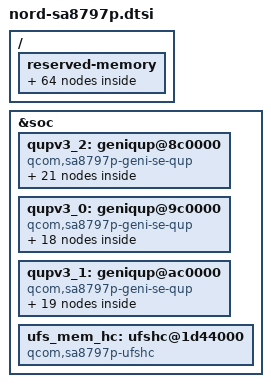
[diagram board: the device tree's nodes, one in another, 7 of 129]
// SPDX-License-Identifier: BSD-3-Clause
/*
 * Copyright (c) Qualcomm Technologies, Inc. and/or its subsidiaries.
 */

#include "nord.dtsi"
#include "scmi-common.dtsi"

/ {
	reserved-memory {
		shmem0: scmi-shmem@d7600000 {
			compatible = "arm,scmi-shmem";
			reg = <0x0 0xd7600000 0x0 0x1000>;
			no-map;
		};

		shmem1: scmi-shmem@d7601000 {
			compatible = "arm,scmi-shmem";
			reg = <0x0 0xd7601000 0x0 0x1000>;
			no-map;
		};

		shmem2: scmi-shmem@d7602000 {
			compatible = "arm,scmi-shmem";
			reg = <0x0 0xd7602000 0x0 0x1000>;
			no-map;
		};

		shmem3: scmi-shmem@d7603000 {
			compatible = "arm,scmi-shmem";
			reg = <0x0 0xd7603000 0x0 0x1000>;
			no-map;
		};

		shmem4: scmi-shmem@d7604000 {
			compatible = "arm,scmi-shmem";
			reg = <0x0 0xd7604000 0x0 0x1000>;
			no-map;
		};

		shmem5: scmi-shmem@d7605000 {
			compatible = "arm,scmi-shmem";
			reg = <0x0 0xd7605000 0x0 0x1000>;
			no-map;
		};

		shmem6: scmi-shmem@d7606000 {
			compatible = "arm,scmi-shmem";
			reg = <0x0 0xd7606000 0x0 0x1000>;
			no-map;
		};

		shmem7: scmi-shmem@d7607000 {
			compatible = "arm,scmi-shmem";
			reg = <0x0 0xd7607000 0x0 0x1000>;
			no-map;
		};

		shmem8: scmi-shmem@d7608000 {
			compatible = "arm,scmi-shmem";
			reg = <0x0 0xd7608000 0x0 0x1000>;
			no-map;
		};

		shmem9: scmi-shmem@d7609000 {
			compatible = "arm,scmi-shmem";
			reg = <0x0 0xd7609000 0x0 0x1000>;
			no-map;
		};

		shmem10: scmi-shmem@d760a000 {
			compatible = "arm,scmi-shmem";
			reg = <0x0 0xd760a000 0x0 0x1000>;
			no-map;
		};

		shmem11: scmi-shmem@d760b000 {
			compatible = "arm,scmi-shmem";
			reg = <0x0 0xd760b000 0x0 0x1000>;
			no-map;
		};

		shmem12: scmi-shmem@d760c000 {
			compatible = "arm,scmi-shmem";
			reg = <0x0 0xd760c000 0x0 0x1000>;
			no-map;
		};

		shmem13: scmi-shmem@d760d000 {
			compatible = "arm,scmi-shmem";
			reg = <0x0 0xd760d000 0x0 0x1000>;
			no-map;
		};

		shmem14: scmi-shmem@d760e000 {
			compatible = "arm,scmi-shmem";
			reg = <0x0 0xd760e000 0x0 0x1000>;
			no-map;
		};

		shmem15: scmi-shmem@d760f000 {
			compatible = "arm,scmi-shmem";
			reg = <0x0 0xd760f000 0x0 0x1000>;
			no-map;
		};

		shmem16: scmi-shmem@d7610000 {
			compatible = "arm,scmi-shmem";
			reg = <0x0 0xd7610000 0x0 0x1000>;
			no-map;
		};

		shmem17: scmi-shmem@d7611000 {
			compatible = "arm,scmi-shmem";
			reg = <0x0 0xd7611000 0x0 0x1000>;
			no-map;
		};

		shmem18: scmi-shmem@d7612000 {
			compatible = "arm,scmi-shmem";
			reg = <0x0 0xd7612000 0x0 0x1000>;
			no-map;
		};

		shmem19: scmi-shmem@d7613000 {
			compatible = "arm,scmi-shmem";
			reg = <0x0 0xd7613000 0x0 0x1000>;
			no-map;
		};

		shmem20: scmi-shmem@d7614000 {
			compatible = "arm,scmi-shmem";
			reg = <0x0 0xd7614000 0x0 0x1000>;
			no-map;
		};

		shmem21: scmi-shmem@d7615000 {
			compatible = "arm,scmi-shmem";
			reg = <0x0 0xd7615000 0x0 0x1000>;
			no-map;
		};

		shmem22: scmi-shmem@d7616000 {
			compatible = "arm,scmi-shmem";
			reg = <0x0 0xd7616000 0x0 0x1000>;
			no-map;
		};

		shmem23: scmi-shmem@d7617000 {
			compatible = "arm,scmi-shmem";
			reg = <0x0 0xd7617000 0x0 0x1000>;
			no-map;
		};

		shmem24: scmi-shmem@d7618000 {
			compatible = "arm,scmi-shmem";
			reg = <0x0 0xd7618000 0x0 0x1000>;
			no-map;
		};

		shmem25: scmi-shmem@d7619000 {
			compatible = "arm,scmi-shmem";
			reg = <0x0 0xd7619000 0x0 0x1000>;
			no-map;
		};

		shmem26: scmi-shmem@d761a000 {
			compatible = "arm,scmi-shmem";
			reg = <0x0 0xd761a000 0x0 0x1000>;
			no-map;
		};

		shmem27: scmi-shmem@d761b000 {
			compatible = "arm,scmi-shmem";
			reg = <0x0 0xd761b000 0x0 0x1000>;
			no-map;
		};

		shmem28: scmi-shmem@d761c000 {
			compatible = "arm,scmi-shmem";
			reg = <0x0 0xd761c000 0x0 0x1000>;
			no-map;
		};

		shmem29: scmi-shmem@d761d000 {
			compatible = "arm,scmi-shmem";
			reg = <0x0 0xd761d000 0x0 0x1000>;
			no-map;
		};

		shmem30: scmi-shmem@d761e000 {
			compatible = "arm,scmi-shmem";
			reg = <0x0 0xd761e000 0x0 0x1000>;
			no-map;
		};

		shmem31: scmi-shmem@d761f000 {
			compatible = "arm,scmi-shmem";
			reg = <0x0 0xd761f000 0x0 0x1000>;
			no-map;
		};

		shmem32: scmi-shmem@d7620000 {
			compatible = "arm,scmi-shmem";
			reg = <0x0 0xd7620000 0x0 0x1000>;
			no-map;
		};

		shmem33: scmi-shmem@d7621000 {
			compatible = "arm,scmi-shmem";
			reg = <0x0 0xd7621000 0x0 0x1000>;
			no-map;
		};

		shmem34: scmi-shmem@d7622000 {
			compatible = "arm,scmi-shmem";
			reg = <0x0 0xd7622000 0x0 0x1000>;
			no-map;
		};

		shmem35: scmi-shmem@d7623000 {
			compatible = "arm,scmi-shmem";
			reg = <0x0 0xd7623000 0x0 0x1000>;
			no-map;
		};

		shmem36: scmi-shmem@d7624000 {
			compatible = "arm,scmi-shmem";
			reg = <0x0 0xd7624000 0x0 0x1000>;
			no-map;
		};

		shmem37: scmi-shmem@d7625000 {
			compatible = "arm,scmi-shmem";
			reg = <0x0 0xd7625000 0x0 0x1000>;
			no-map;
		};

		shmem38: scmi-shmem@d7626000 {
			compatible = "arm,scmi-shmem";
			reg = <0x0 0xd7626000 0x0 0x1000>;
			no-map;
		};

		shmem39: scmi-shmem@d7627000 {
			compatible = "arm,scmi-shmem";
			reg = <0x0 0xd7627000 0x0 0x1000>;
			no-map;
		};

		shmem40: scmi-shmem@d7628000 {
			compatible = "arm,scmi-shmem";
			reg = <0x0 0xd7628000 0x0 0x1000>;
			no-map;
		};

		shmem41: scmi-shmem@d7629000 {
			compatible = "arm,scmi-shmem";
			reg = <0x0 0xd7629000 0x0 0x1000>;
			no-map;
		};

		shmem42: scmi-shmem@d762a000 {
			compatible = "arm,scmi-shmem";
			reg = <0x0 0xd762a000 0x0 0x1000>;
			no-map;
		};

		shmem43: scmi-shmem@d762b000 {
			compatible = "arm,scmi-shmem";
			reg = <0x0 0xd762b000 0x0 0x1000>;
			no-map;
		};

		shmem44: scmi-shmem@d762c000 {
			compatible = "arm,scmi-shmem";
			reg = <0x0 0xd762c000 0x0 0x1000>;
			no-map;
		};

		shmem45: scmi-shmem@d762d000 {
			compatible = "arm,scmi-shmem";
			reg = <0x0 0xd762d000 0x0 0x1000>;
			no-map;
		};

		shmem46: scmi-shmem@d762e000 {
			compatible = "arm,scmi-shmem";
			reg = <0x0 0xd762e000 0x0 0x1000>;
			no-map;
		};

		shmem47: scmi-shmem@d762f000 {
			compatible = "arm,scmi-shmem";
			reg = <0x0 0xd762f000 0x0 0x1000>;
			no-map;
		};

		shmem48: scmi-shmem@d7630000 {
			compatible = "arm,scmi-shmem";
			reg = <0x0 0xd7630000 0x0 0x1000>;
			no-map;
		};

		shmem49: scmi-shmem@d7631000 {
			compatible = "arm,scmi-shmem";
			reg = <0x0 0xd7631000 0x0 0x1000>;
			no-map;
		};

		shmem50: scmi-shmem@d7632000 {
			compatible = "arm,scmi-shmem";
			reg = <0x0 0xd7632000 0x0 0x1000>;
			no-map;
		};

		shmem51: scmi-shmem@d7633000 {
			compatible = "arm,scmi-shmem";
			reg = <0x0 0xd7633000 0x0 0x1000>;
			no-map;
		};

		shmem52: scmi-shmem@d7634000 {
			compatible = "arm,scmi-shmem";
			reg = <0x0 0xd7634000 0x0 0x1000>;
			no-map;
		};

		shmem53: scmi-shmem@d7635000 {
			compatible = "arm,scmi-shmem";
			reg = <0x0 0xd7635000 0x0 0x1000>;
			no-map;
		};

		shmem54: scmi-shmem@d7636000 {
			compatible = "arm,scmi-shmem";
			reg = <0x0 0xd7636000 0x0 0x1000>;
			no-map;
		};

		shmem55: scmi-shmem@d7637000 {
			compatible = "arm,scmi-shmem";
			reg = <0x0 0xd7637000 0x0 0x1000>;
			no-map;
		};

		shmem56: scmi-shmem@d7638000 {
			compatible = "arm,scmi-shmem";
			reg = <0x0 0xd7638000 0x0 0x1000>;
			no-map;
		};

		shmem57: scmi-shmem@d7639000 {
			compatible = "arm,scmi-shmem";
			reg = <0x0 0xd7639000 0x0 0x1000>;
			no-map;
		};

		shmem58: scmi-shmem@d763a000 {
			compatible = "arm,scmi-shmem";
			reg = <0x0 0xd763a000 0x0 0x1000>;
			no-map;
		};

		shmem59: scmi-shmem@d763b000 {
			compatible = "arm,scmi-shmem";
			reg = <0x0 0xd763b000 0x0 0x1000>;
			no-map;
		};

		shmem60: scmi-shmem@d763c000 {
			compatible = "arm,scmi-shmem";
			reg = <0x0 0xd763c000 0x0 0x1000>;
			no-map;
		};

		shmem61: scmi-shmem@d763d000 {
			compatible = "arm,scmi-shmem";
			reg = <0x0 0xd763d000 0x0 0x1000>;
			no-map;
		};

		shmem62: scmi-shmem@d763e000 {
			compatible = "arm,scmi-shmem";
			reg = <0x0 0xd763e000 0x0 0x1000>;
			no-map;
		};

		shmem63: scmi-shmem@d763f000 {
			compatible = "arm,scmi-shmem";
			reg = <0x0 0xd763f000 0x0 0x1000>;
			no-map;
		};
	};
};

&soc {
	qupv3_2: geniqup@8c0000 {
		compatible = "qcom,sa8797p-geni-se-qup",
			     "qcom,sa8255p-geni-se-qup";

		i2c14: i2c@880000 {
			compatible = "qcom,sa8797p-geni-i2c",
				     "qcom,sa8255p-geni-i2c";
			power-domains = <&scmi11_pd 14>,
					<&scmi11_dvfs 14>;
			power-domain-names = "power",
					     "perf";
		};

		spi14: spi@880000 {
			compatible = "qcom,sa8797p-geni-spi",
				     "qcom,sa8255p-geni-spi";
			power-domains = <&scmi11_pd 14>,
					<&scmi11_dvfs 14>;
			power-domain-names = "power",
					     "perf";
		};

		uart14: serial@880000 {
			compatible = "qcom,sa8797p-geni-uart",
				     "qcom,sa8255p-geni-uart";
			power-domains = <&scmi11_pd 14>,
					<&scmi11_dvfs 14>;
			power-domain-names = "power",
					     "perf";
		};

		i2c15: i2c@884000 {
			compatible = "qcom,sa8797p-geni-i2c",
				     "qcom,sa8255p-geni-i2c";
			power-domains = <&scmi11_pd 15>,
					<&scmi11_dvfs 15>;
			power-domain-names = "power",
					     "perf";
		};

		spi15: spi@884000 {
			compatible = "qcom,sa8797p-geni-spi",
				     "qcom,sa8255p-geni-spi";
			power-domains = <&scmi11_pd 15>,
					<&scmi11_dvfs 15>;
			power-domain-names = "power",
					     "perf";
		};

		uart15: serial@884000 {
			compatible = "qcom,sa8797p-geni-debug-uart",
				     "qcom,sa8255p-geni-debug-uart";
			power-domains = <&scmi11_pd 15>,
					<&scmi11_dvfs 15>;
			power-domain-names = "power",
					     "perf";
		};

		i2c16: i2c@888000 {
			compatible = "qcom,sa8797p-geni-i2c",
				     "qcom,sa8255p-geni-i2c";
			power-domains = <&scmi11_pd 16>,
					<&scmi11_dvfs 16>;
			power-domain-names = "power",
					     "perf";
		};

		spi16: spi@888000 {
			compatible = "qcom,sa8797p-geni-spi",
				     "qcom,sa8255p-geni-spi";
			power-domains = <&scmi11_pd 16>,
					<&scmi11_dvfs 16>;
			power-domain-names = "power",
					     "perf";
		};

		uart16: serial@888000 {
			compatible = "qcom,sa8797p-geni-uart",
				     "qcom,sa8255p-geni-uart";
			power-domains = <&scmi11_pd 16>,
					<&scmi11_dvfs 16>;
			power-domain-names = "power",
					     "perf";
		};

		i2c17: i2c@88c000 {
			compatible = "qcom,sa8797p-geni-i2c",
				     "qcom,sa8255p-geni-i2c";
			power-domains = <&scmi11_pd 17>,
					<&scmi11_dvfs 17>;
			power-domain-names = "power",
					     "perf";
		};

		spi17: spi@88c000 {
			compatible = "qcom,sa8797p-geni-spi",
				     "qcom,sa8255p-geni-spi";
			power-domains = <&scmi11_pd 17>,
					<&scmi11_dvfs 17>;
			power-domain-names = "power",
					     "perf";
		};

		uart17: serial@88c000 {
			compatible = "qcom,sa8797p-geni-uart",
				     "qcom,sa8255p-geni-uart";
			power-domains = <&scmi11_pd 17>,
					<&scmi11_dvfs 17>;
			power-domain-names = "power",
					     "perf";
		};

		i2c18: i2c@890000 {
			compatible = "qcom,sa8797p-geni-i2c",
				     "qcom,sa8255p-geni-i2c";
			power-domains = <&scmi11_pd 18>,
					<&scmi11_dvfs 18>;
			power-domain-names = "power",
					     "perf";
		};

		spi18: spi@890000 {
			compatible = "qcom,sa8797p-geni-spi",
				     "qcom,sa8255p-geni-spi";
			power-domains = <&scmi11_pd 18>,
					<&scmi11_dvfs 18>;
			power-domain-names = "power",
					     "perf";
		};

		uart18: serial@890000 {
			compatible = "qcom,sa8797p-geni-uart",
				     "qcom,sa8255p-geni-uart";
			power-domains = <&scmi11_pd 18>,
					<&scmi11_dvfs 18>;
			power-domain-names = "power",
					     "perf";
		};

		i2c19: i2c@894000 {
			compatible = "qcom,sa8797p-geni-i2c",
				     "qcom,sa8255p-geni-i2c";
			power-domains = <&scmi11_pd 19>,
					<&scmi11_dvfs 19>;
			power-domain-names = "power",
					     "perf";
		};

		spi19: spi@894000 {
			compatible = "qcom,sa8797p-geni-spi",
				     "qcom,sa8255p-geni-spi";
			power-domains = <&scmi11_pd 19>,
					<&scmi11_dvfs 19>;
			power-domain-names = "power",
					     "perf";
		};

		uart19: serial@894000 {
			compatible = "qcom,sa8797p-geni-uart",
				     "qcom,sa8255p-geni-uart";
			power-domains = <&scmi11_pd 19>,
					<&scmi11_dvfs 19>;
			power-domain-names = "power",
					     "perf";
		};

		i2c20: i2c@898000 {
			compatible = "qcom,sa8797p-geni-i2c",
				     "qcom,sa8255p-geni-i2c";
			power-domains = <&scmi11_pd 20>,
					<&scmi11_dvfs 20>;
			power-domain-names = "power",
					     "perf";
		};

		spi20: spi@898000 {
			compatible = "qcom,sa8797p-geni-spi",
				     "qcom,sa8255p-geni-spi";
			power-domains = <&scmi11_pd 20>,
					<&scmi11_dvfs 20>;
			power-domain-names = "power",
					     "perf";
		};

		uart20: serial@898000 {
			compatible = "qcom,sa8797p-geni-uart",
				     "qcom,sa8255p-geni-uart";
			power-domains = <&scmi11_pd 20>,
					<&scmi11_dvfs 20>;
			power-domain-names = "power",
					     "perf";
		};
	};

	qupv3_0: geniqup@9c0000 {
		compatible = "qcom,sa8797p-geni-se-qup",
			     "qcom,sa8255p-geni-se-qup";

		i2c0: i2c@980000 {
			compatible = "qcom,sa8797p-geni-i2c",
				     "qcom,sa8255p-geni-i2c";
			power-domains = <&scmi11_pd 0>,
					<&scmi11_dvfs 0>;
			power-domain-names = "power",
					     "perf";
		};

		spi0: spi@980000 {
			compatible = "qcom,sa8797p-geni-spi",
				     "qcom,sa8255p-geni-spi";
			power-domains = <&scmi11_pd 0>,
					<&scmi11_dvfs 0>;
			power-domain-names = "power",
					     "perf";
		};

		uart0: serial@980000 {
			compatible = "qcom,sa8797p-geni-uart",
				     "qcom,sa8255p-geni-uart";
			power-domains = <&scmi11_pd 0>,
					<&scmi11_dvfs 0>;
			power-domain-names = "power",
					     "perf";
		};

		i2c1: i2c@984000 {
			compatible = "qcom,sa8797p-geni-i2c",
				     "qcom,sa8255p-geni-i2c";
			power-domains = <&scmi11_pd 1>,
					<&scmi11_dvfs 1>;
			power-domain-names = "power",
					     "perf";
		};

		spi1: spi@984000 {
			compatible = "qcom,sa8797p-geni-spi",
				     "qcom,sa8255p-geni-spi";
			power-domains = <&scmi11_pd 1>,
					<&scmi11_dvfs 1>;
			power-domain-names = "power",
					     "perf";
		};

		uart1: serial@984000 {
			compatible = "qcom,sa8797p-geni-uart",
				     "qcom,sa8255p-geni-uart";
			power-domains = <&scmi11_pd 1>,
					<&scmi11_dvfs 1>;
			power-domain-names = "power",
					     "perf";
		};

		i2c2: i2c@988000 {
			compatible = "qcom,sa8797p-geni-i2c",
				     "qcom,sa8255p-geni-i2c";
			power-domains = <&scmi11_pd 2>,
					<&scmi11_dvfs 2>;
			power-domain-names = "power",
					     "perf";
		};

		spi2: spi@988000 {
			compatible = "qcom,sa8797p-geni-spi",
				     "qcom,sa8255p-geni-spi";
			power-domains = <&scmi11_pd 2>,
					<&scmi11_dvfs 2>;
			power-domain-names = "power",
					     "perf";
		};

		uart2: serial@988000 {
			compatible = "qcom,sa8797p-geni-uart",
				     "qcom,sa8255p-geni-uart";
			power-domains = <&scmi11_pd 2>,
					<&scmi11_dvfs 2>;
			power-domain-names = "power",
					     "perf";
		};

		i2c3: i2c@98c000 {
			compatible = "qcom,sa8797p-geni-i2c",
				     "qcom,sa8255p-geni-i2c";
			power-domains = <&scmi11_pd 3>,
					<&scmi11_dvfs 3>;
			power-domain-names = "power",
					     "perf";
		};

		spi3: spi@98c000 {
			compatible = "qcom,sa8797p-geni-spi",
				     "qcom,sa8255p-geni-spi";
			power-domains = <&scmi11_pd 3>,
					<&scmi11_dvfs 3>;
			power-domain-names = "power",
					     "perf";
		};

		uart3: serial@98c000 {
			compatible = "qcom,sa8797p-geni-uart",
				     "qcom,sa8255p-geni-uart";
			power-domains = <&scmi11_pd 3>,
					<&scmi11_dvfs 3>;
			power-domain-names = "power",
					     "perf";
		};

		i2c4: i2c@990000 {
			compatible = "qcom,sa8797p-geni-i2c",
				     "qcom,sa8255p-geni-i2c";
			power-domains = <&scmi11_pd 4>,
					<&scmi11_dvfs 4>;
			power-domain-names = "power",
					     "perf";
		};

		spi4: spi@990000 {
			compatible = "qcom,sa8797p-geni-spi",
				     "qcom,sa8255p-geni-spi";
			power-domains = <&scmi11_pd 4>,
					<&scmi11_dvfs 4>;
			power-domain-names = "power",
					     "perf";
		};

		uart4: serial@990000 {
			compatible = "qcom,sa8797p-geni-uart",
				     "qcom,sa8255p-geni-uart";
			power-domains = <&scmi11_pd 4>,
					<&scmi11_dvfs 4>;
			power-domain-names = "power",
					     "perf";
		};

		i2c5: i2c@994000 {
			compatible = "qcom,sa8797p-geni-i2c",
				     "qcom,sa8255p-geni-i2c";
			power-domains = <&scmi11_pd 5>,
					<&scmi11_dvfs 5>;
			power-domain-names = "power",
					     "perf";
		};

		spi5: spi@994000 {
			compatible = "qcom,sa8797p-geni-spi",
				     "qcom,sa8255p-geni-spi";
			power-domains = <&scmi11_pd 5>,
					<&scmi11_dvfs 5>;
			power-domain-names = "power",
					     "perf";
		};

		uart5: serial@994000 {
			compatible = "qcom,sa8797p-geni-uart",
				     "qcom,sa8255p-geni-uart";
			power-domains = <&scmi11_pd 5>,
					<&scmi11_dvfs 5>;
			power-domain-names = "power",
					     "perf";
		};
	};

	qupv3_1: geniqup@ac0000 {
		compatible = "qcom,sa8797p-geni-se-qup",
			     "qcom,sa8255p-geni-se-qup";

		i2c7: i2c@a80000 {
			compatible = "qcom,sa8797p-geni-i2c",
				     "qcom,sa8255p-geni-i2c";
			power-domains = <&scmi11_pd 7>,
					<&scmi11_dvfs 7>;
			power-domain-names = "power",
					     "perf";
		};

		spi7: spi@a80000 {
			compatible = "qcom,sa8797p-geni-spi",
				     "qcom,sa8255p-geni-spi";
			power-domains = <&scmi11_pd 7>,
					<&scmi11_dvfs 7>;
			power-domain-names = "power",
					     "perf";
		};

		uart7: serial@a80000 {
			compatible = "qcom,sa8797p-geni-uart",
				     "qcom,sa8255p-geni-uart";
			power-domains = <&scmi11_pd 7>,
					<&scmi11_dvfs 7>;
			power-domain-names = "power",
					     "perf";
		};

		i2c8: i2c@a84000 {
			compatible = "qcom,sa8797p-geni-i2c",
				     "qcom,sa8255p-geni-i2c";
			power-domains = <&scmi11_pd 8>,
					<&scmi11_dvfs 8>;
			power-domain-names = "power",
					     "perf";
		};

		spi8: spi@a84000 {
			compatible = "qcom,sa8797p-geni-spi",
				     "qcom,sa8255p-geni-spi";
			power-domains = <&scmi11_pd 8>,
					<&scmi11_dvfs 8>;
			power-domain-names = "power",
					     "perf";
		};

		uart8: serial@a84000 {
			compatible = "qcom,sa8797p-geni-uart",
				     "qcom,sa8255p-geni-uart";
			power-domains = <&scmi11_pd 8>,
					<&scmi11_dvfs 8>;
			power-domain-names = "power",
					     "perf";
		};

		i2c9: i2c@a88000 {
			compatible = "qcom,sa8797p-geni-i2c",
				     "qcom,sa8255p-geni-i2c";
			power-domains = <&scmi11_pd 9>,
					<&scmi11_dvfs 9>;
			power-domain-names = "power",
					     "perf";
		};

		uart9: serial@a88000 {
			compatible = "qcom,sa8797p-geni-uart",
				     "qcom,sa8255p-geni-uart";
			power-domains = <&scmi11_pd 9>,
					<&scmi11_dvfs 9>;
			power-domain-names = "power",
					     "perf";
		};

		i2c10: i2c@a8c000 {
			compatible = "qcom,sa8797p-geni-i2c",
				     "qcom,sa8255p-geni-i2c";
			power-domains = <&scmi11_pd 10>,
					<&scmi11_dvfs 10>;
			power-domain-names = "power",
					     "perf";
		};

		uart10: serial@a8c000 {
			compatible = "qcom,sa8797p-geni-uart",
				     "qcom,sa8255p-geni-uart";
			power-domains = <&scmi11_pd 10>,
					<&scmi11_dvfs 10>;
			power-domain-names = "power",
					     "perf";
		};

		i2c11: i2c@a90000 {
			compatible = "qcom,sa8797p-geni-i2c",
				     "qcom,sa8255p-geni-i2c";
			power-domains = <&scmi11_pd 11>,
					<&scmi11_dvfs 11>;
			power-domain-names = "power",
					     "perf";
		};

		spi11: spi@a90000 {
			compatible = "qcom,sa8797p-geni-spi",
				     "qcom,sa8255p-geni-spi";
			power-domains = <&scmi11_pd 11>,
					<&scmi11_dvfs 11>;
			power-domain-names = "power",
					     "perf";
		};

		uart11: serial@a90000 {
			compatible = "qcom,sa8797p-geni-uart",
				     "qcom,sa8255p-geni-uart";
			power-domains = <&scmi11_pd 11>,
					<&scmi11_dvfs 11>;
			power-domain-names = "power",
					     "perf";
		};

		i2c12: i2c@a94000 {
			compatible = "qcom,sa8797p-geni-i2c",
				     "qcom,sa8255p-geni-i2c";
			power-domains = <&scmi11_pd 12>,
					<&scmi11_dvfs 12>;
			power-domain-names = "power",
					     "perf";
		};

		spi12: spi@a94000 {
			compatible = "qcom,sa8797p-geni-spi",
				     "qcom,sa8255p-geni-spi";
			power-domains = <&scmi11_pd 12>,
					<&scmi11_dvfs 12>;
			power-domain-names = "power",
					     "perf";
		};

		uart12: serial@a94000 {
			compatible = "qcom,sa8797p-geni-uart",
				     "qcom,sa8255p-geni-uart";
			power-domains = <&scmi11_pd 12>,
					<&scmi11_dvfs 12>;
			power-domain-names = "power",
					     "perf";
		};

		i2c13: i2c@a98000 {
			compatible = "qcom,sa8797p-geni-i2c",
				     "qcom,sa8255p-geni-i2c";
			power-domains = <&scmi11_pd 13>,
					<&scmi11_dvfs 13>;
			power-domain-names = "power",
					     "perf";
		};

		spi13: spi@a98000 {
			compatible = "qcom,sa8797p-geni-spi",
				     "qcom,sa8255p-geni-spi";
			power-domains = <&scmi11_pd 13>,
					<&scmi11_dvfs 13>;
			power-domain-names = "power",
					     "perf";
		};

		uart13: serial@a98000 {
			compatible = "qcom,sa8797p-geni-uart",
				     "qcom,sa8255p-geni-uart";
			power-domains = <&scmi11_pd 13>,
					<&scmi11_dvfs 13>;
			power-domain-names = "power",
					     "perf";
		};
	};

	ufs_mem_hc: ufshc@1d44000 {
		compatible = "qcom,sa8797p-ufshc",
			     "qcom,sa8255p-ufshc";
		reg = <0x0 0x01d44000 0x0 0x3000>;
		power-domains = <&scmi3_pd 0>;
	};
};
